VERSION "CAN-LoRa telemetry, protocol version 2"

NS_ :

BS_:

BU_: NODE0_HUB NODE1_FRONT NODE2_REAR NODE3_MOTOR HUB

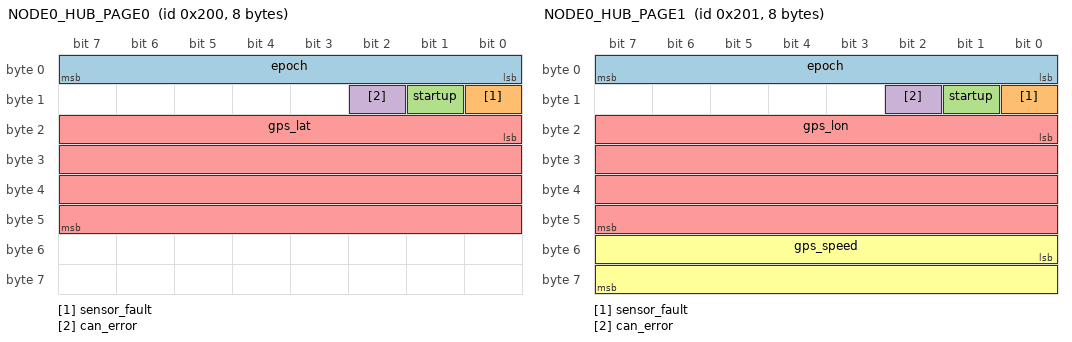
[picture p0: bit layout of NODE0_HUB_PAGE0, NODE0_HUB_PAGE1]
BO_ 512 NODE0_HUB_PAGE0: 8 NODE0_HUB
 SG_ epoch : 0|8@1+ (1,0) [0|255] "" HUB
 SG_ sensor_fault : 8|1@1+ (1,0) [0|1] "" HUB
 SG_ startup : 9|1@1+ (1,0) [0|1] "" HUB
 SG_ can_error : 10|1@1+ (1,0) [0|1] "" HUB
 SG_ gps_lat : 16|32@1- (0.0000001,0) [-214.7483648|214.7483647] "deg" HUB

BO_ 513 NODE0_HUB_PAGE1: 8 NODE0_HUB
 SG_ epoch : 0|8@1+ (1,0) [0|255] "" HUB
 SG_ sensor_fault : 8|1@1+ (1,0) [0|1] "" HUB
 SG_ startup : 9|1@1+ (1,0) [0|1] "" HUB
 SG_ can_error : 10|1@1+ (1,0) [0|1] "" HUB
 SG_ gps_lon : 16|32@1- (0.0000001,0) [-214.7483648|214.7483647] "deg" HUB
 SG_ gps_speed : 48|16@1- (0.01,0) [-327.68|327.67] "mph" HUB

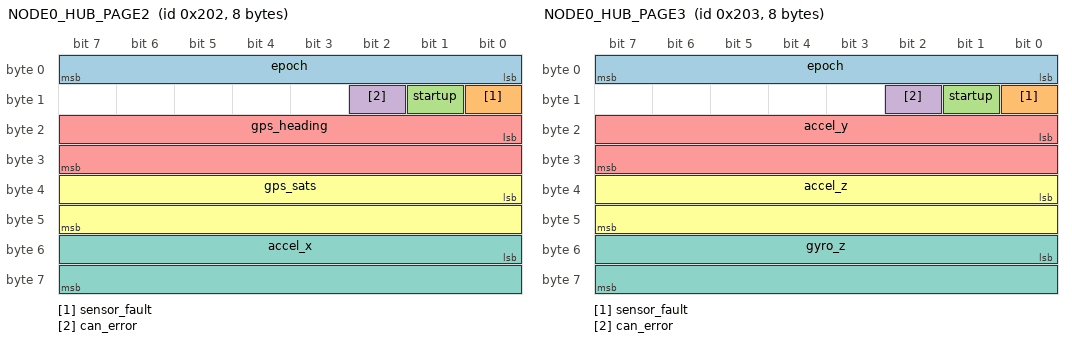
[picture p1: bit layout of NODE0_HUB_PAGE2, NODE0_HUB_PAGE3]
BO_ 514 NODE0_HUB_PAGE2: 8 NODE0_HUB
 SG_ epoch : 0|8@1+ (1,0) [0|255] "" HUB
 SG_ sensor_fault : 8|1@1+ (1,0) [0|1] "" HUB
 SG_ startup : 9|1@1+ (1,0) [0|1] "" HUB
 SG_ can_error : 10|1@1+ (1,0) [0|1] "" HUB
 SG_ gps_heading : 16|16@1- (0.02,0) [-655.36|655.34] "deg" HUB
 SG_ gps_sats : 32|16@1- (1,0) [-32768|32767] "count" HUB
 SG_ accel_x : 48|16@1- (0.001,0) [-32.768|32.767] "g" HUB

BO_ 515 NODE0_HUB_PAGE3: 8 NODE0_HUB
 SG_ epoch : 0|8@1+ (1,0) [0|255] "" HUB
 SG_ sensor_fault : 8|1@1+ (1,0) [0|1] "" HUB
 SG_ startup : 9|1@1+ (1,0) [0|1] "" HUB
 SG_ can_error : 10|1@1+ (1,0) [0|1] "" HUB
 SG_ accel_y : 16|16@1- (0.001,0) [-32.768|32.767] "g" HUB
 SG_ accel_z : 32|16@1- (0.001,0) [-32.768|32.767] "g" HUB
 SG_ gyro_z : 48|16@1- (0.01,0) [-327.68|327.67] "deg/s" HUB

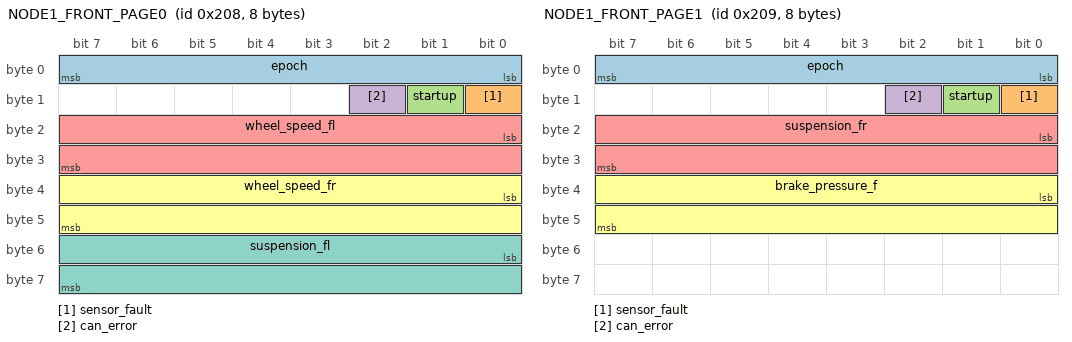
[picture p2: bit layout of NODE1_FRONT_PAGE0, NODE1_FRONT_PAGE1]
BO_ 520 NODE1_FRONT_PAGE0: 8 NODE1_FRONT
 SG_ epoch : 0|8@1+ (1,0) [0|255] "" HUB
 SG_ sensor_fault : 8|1@1+ (1,0) [0|1] "" HUB
 SG_ startup : 9|1@1+ (1,0) [0|1] "" HUB
 SG_ can_error : 10|1@1+ (1,0) [0|1] "" HUB
 SG_ wheel_speed_fl : 16|16@1- (0.01,0) [-327.68|327.67] "mph" HUB
 SG_ wheel_speed_fr : 32|16@1- (0.01,0) [-327.68|327.67] "mph" HUB
 SG_ suspension_fl : 48|16@1- (0.01,0) [-327.68|327.67] "mm" HUB

BO_ 521 NODE1_FRONT_PAGE1: 8 NODE1_FRONT
 SG_ epoch : 0|8@1+ (1,0) [0|255] "" HUB
 SG_ sensor_fault : 8|1@1+ (1,0) [0|1] "" HUB
 SG_ startup : 9|1@1+ (1,0) [0|1] "" HUB
 SG_ can_error : 10|1@1+ (1,0) [0|1] "" HUB
 SG_ suspension_fr : 16|16@1- (0.01,0) [-327.68|327.67] "mm" HUB
 SG_ brake_pressure_f : 32|16@1- (0.1,0) [-3276.8|3276.7000000000003] "psi" HUB

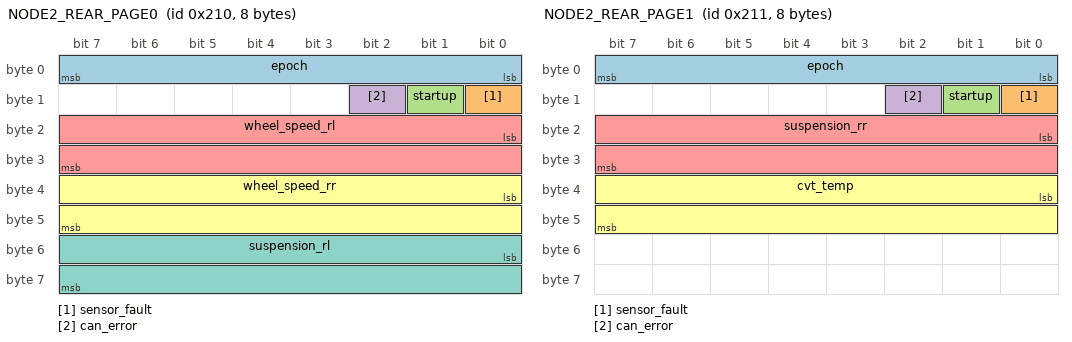
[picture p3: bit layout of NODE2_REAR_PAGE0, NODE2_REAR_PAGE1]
BO_ 528 NODE2_REAR_PAGE0: 8 NODE2_REAR
 SG_ epoch : 0|8@1+ (1,0) [0|255] "" HUB
 SG_ sensor_fault : 8|1@1+ (1,0) [0|1] "" HUB
 SG_ startup : 9|1@1+ (1,0) [0|1] "" HUB
 SG_ can_error : 10|1@1+ (1,0) [0|1] "" HUB
 SG_ wheel_speed_rl : 16|16@1- (0.01,0) [-327.68|327.67] "mph" HUB
 SG_ wheel_speed_rr : 32|16@1- (0.01,0) [-327.68|327.67] "mph" HUB
 SG_ suspension_rl : 48|16@1- (0.01,0) [-327.68|327.67] "mm" HUB

BO_ 529 NODE2_REAR_PAGE1: 8 NODE2_REAR
 SG_ epoch : 0|8@1+ (1,0) [0|255] "" HUB
 SG_ sensor_fault : 8|1@1+ (1,0) [0|1] "" HUB
 SG_ startup : 9|1@1+ (1,0) [0|1] "" HUB
 SG_ can_error : 10|1@1+ (1,0) [0|1] "" HUB
 SG_ suspension_rr : 16|16@1- (0.01,0) [-327.68|327.67] "mm" HUB
 SG_ cvt_temp : 32|16@1- (0.01,0) [-327.68|327.67] "degC" HUB

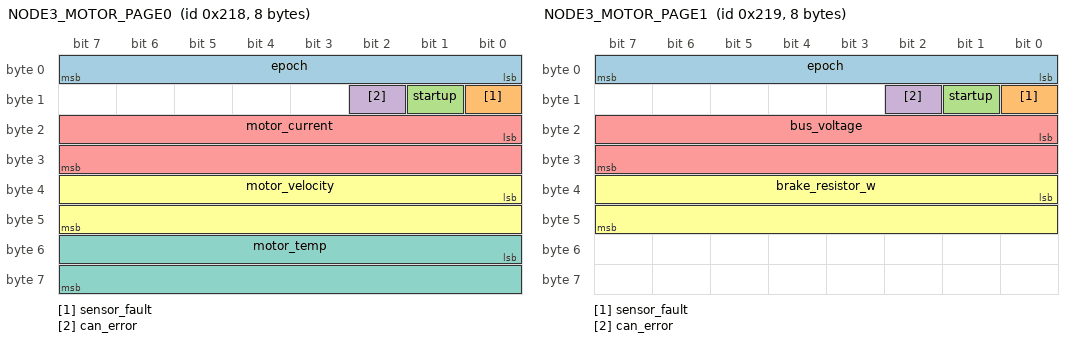
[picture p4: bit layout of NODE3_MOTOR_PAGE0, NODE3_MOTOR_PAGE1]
BO_ 536 NODE3_MOTOR_PAGE0: 8 NODE3_MOTOR
 SG_ epoch : 0|8@1+ (1,0) [0|255] "" HUB
 SG_ sensor_fault : 8|1@1+ (1,0) [0|1] "" HUB
 SG_ startup : 9|1@1+ (1,0) [0|1] "" HUB
 SG_ can_error : 10|1@1+ (1,0) [0|1] "" HUB
 SG_ motor_current : 16|16@1- (0.01,0) [-327.68|327.67] "A" HUB
 SG_ motor_velocity : 32|16@1- (1,0) [-32768|32767] "rpm" HUB
 SG_ motor_temp : 48|16@1- (0.01,0) [-327.68|327.67] "degC" HUB

BO_ 537 NODE3_MOTOR_PAGE1: 8 NODE3_MOTOR
 SG_ epoch : 0|8@1+ (1,0) [0|255] "" HUB
 SG_ sensor_fault : 8|1@1+ (1,0) [0|1] "" HUB
 SG_ startup : 9|1@1+ (1,0) [0|1] "" HUB
 SG_ can_error : 10|1@1+ (1,0) [0|1] "" HUB
 SG_ bus_voltage : 16|16@1- (0.01,0) [-327.68|327.67] "V" HUB
 SG_ brake_resistor_w : 32|16@1- (0.01,0) [-327.68|327.67] "W" HUB

CM_ "Generated by tools/gen_dbc_v2.py on 2026-08-16. Do not edit by hand - edit TLM2_CHANNELS in protocol/telemetry_proto_v2.c and regenerate.";
CM_ BU_ NODE0_HUB "Hub - GPS/IMU, sends 4 page(s) per burst";
CM_ BO_ 512 "Hub - GPS/IMU page 0 of 4, part of a burst sent every 100 ms. All pages of a burst share the same epoch value.";
CM_ SG_ 512 epoch "Increments once per BURST (all pages of one transmit cycle share a value), not once per CAN frame. A gap here means a whole burst was lost or torn, not just this page.";
CM_ SG_ 512 sensor_fault "node could not read a sensor";
CM_ SG_ 512 startup "first few seconds after reset";
CM_ SG_ 512 can_error "node saw bus errors / recovered";
CM_ BO_ 513 "Hub - GPS/IMU page 1 of 4, part of a burst sent every 100 ms. All pages of a burst share the same epoch value.";
CM_ SG_ 513 epoch "Increments once per BURST (all pages of one transmit cycle share a value), not once per CAN frame. A gap here means a whole burst was lost or torn, not just this page.";
CM_ SG_ 513 sensor_fault "node could not read a sensor";
CM_ SG_ 513 startup "first few seconds after reset";
CM_ SG_ 513 can_error "node saw bus errors / recovered";
CM_ BO_ 514 "Hub - GPS/IMU page 2 of 4, part of a burst sent every 100 ms. All pages of a burst share the same epoch value.";
CM_ SG_ 514 epoch "Increments once per BURST (all pages of one transmit cycle share a value), not once per CAN frame. A gap here means a whole burst was lost or torn, not just this page.";
CM_ SG_ 514 sensor_fault "node could not read a sensor";
CM_ SG_ 514 startup "first few seconds after reset";
CM_ SG_ 514 can_error "node saw bus errors / recovered";
CM_ BO_ 515 "Hub - GPS/IMU page 3 of 4, part of a burst sent every 100 ms. All pages of a burst share the same epoch value.";
CM_ SG_ 515 epoch "Increments once per BURST (all pages of one transmit cycle share a value), not once per CAN frame. A gap here means a whole burst was lost or torn, not just this page.";
CM_ SG_ 515 sensor_fault "node could not read a sensor";
CM_ SG_ 515 startup "first few seconds after reset";
CM_ SG_ 515 can_error "node saw bus errors / recovered";
CM_ BU_ NODE1_FRONT "Front, sends 2 page(s) per burst";
CM_ BO_ 520 "Front page 0 of 2, part of a burst sent every 100 ms. All pages of a burst share the same epoch value.";
CM_ SG_ 520 epoch "Increments once per BURST (all pages of one transmit cycle share a value), not once per CAN frame. A gap here means a whole burst was lost or torn, not just this page.";
CM_ SG_ 520 sensor_fault "node could not read a sensor";
CM_ SG_ 520 startup "first few seconds after reset";
CM_ SG_ 520 can_error "node saw bus errors / recovered";
CM_ BO_ 521 "Front page 1 of 2, part of a burst sent every 100 ms. All pages of a burst share the same epoch value.";
CM_ SG_ 521 epoch "Increments once per BURST (all pages of one transmit cycle share a value), not once per CAN frame. A gap here means a whole burst was lost or torn, not just this page.";
CM_ SG_ 521 sensor_fault "node could not read a sensor";
CM_ SG_ 521 startup "first few seconds after reset";
CM_ SG_ 521 can_error "node saw bus errors / recovered";
CM_ BU_ NODE2_REAR "Rear, sends 2 page(s) per burst";
CM_ BO_ 528 "Rear page 0 of 2, part of a burst sent every 100 ms. All pages of a burst share the same epoch value.";
CM_ SG_ 528 epoch "Increments once per BURST (all pages of one transmit cycle share a value), not once per CAN frame. A gap here means a whole burst was lost or torn, not just this page.";
CM_ SG_ 528 sensor_fault "node could not read a sensor";
CM_ SG_ 528 startup "first few seconds after reset";
CM_ SG_ 528 can_error "node saw bus errors / recovered";
CM_ BO_ 529 "Rear page 1 of 2, part of a burst sent every 100 ms. All pages of a burst share the same epoch value.";
CM_ SG_ 529 epoch "Increments once per BURST (all pages of one transmit cycle share a value), not once per CAN frame. A gap here means a whole burst was lost or torn, not just this page.";
CM_ SG_ 529 sensor_fault "node could not read a sensor";
CM_ SG_ 529 startup "first few seconds after reset";
CM_ SG_ 529 can_error "node saw bus errors / recovered";
CM_ BU_ NODE3_MOTOR "E-CVT / Motor, sends 2 page(s) per burst";
CM_ BO_ 536 "E-CVT / Motor page 0 of 2, part of a burst sent every 100 ms. All pages of a burst share the same epoch value.";
CM_ SG_ 536 epoch "Increments once per BURST (all pages of one transmit cycle share a value), not once per CAN frame. A gap here means a whole burst was lost or torn, not just this page.";
CM_ SG_ 536 sensor_fault "node could not read a sensor";
CM_ SG_ 536 startup "first few seconds after reset";
CM_ SG_ 536 can_error "node saw bus errors / recovered";
CM_ BO_ 537 "E-CVT / Motor page 1 of 2, part of a burst sent every 100 ms. All pages of a burst share the same epoch value.";
CM_ SG_ 537 epoch "Increments once per BURST (all pages of one transmit cycle share a value), not once per CAN frame. A gap here means a whole burst was lost or torn, not just this page.";
CM_ SG_ 537 sensor_fault "node could not read a sensor";
CM_ SG_ 537 startup "first few seconds after reset";
CM_ SG_ 537 can_error "node saw bus errors / recovered";
CM_ BU_ HUB "STM32L476RG, aggregates the bus and uplinks snapshots over LoRa";

BA_DEF_ BO_  "GenMsgCycleTime" INT 0 65535;
BA_DEF_ "BusType" STRING ;
BA_DEF_DEF_  "GenMsgCycleTime" 0;
BA_DEF_DEF_  "BusType" "CAN";
BA_ "GenMsgCycleTime" BO_ 512 100;
BA_ "GenMsgCycleTime" BO_ 513 100;
BA_ "GenMsgCycleTime" BO_ 514 100;
BA_ "GenMsgCycleTime" BO_ 515 100;
BA_ "GenMsgCycleTime" BO_ 520 100;
BA_ "GenMsgCycleTime" BO_ 521 100;
BA_ "GenMsgCycleTime" BO_ 528 100;
BA_ "GenMsgCycleTime" BO_ 529 100;
BA_ "GenMsgCycleTime" BO_ 536 100;
BA_ "GenMsgCycleTime" BO_ 537 100;

VAL_ 512 sensor_fault 1 "yes" 0 "no";
VAL_ 512 startup 1 "yes" 0 "no";
VAL_ 512 can_error 1 "yes" 0 "no";
VAL_ 513 sensor_fault 1 "yes" 0 "no";
VAL_ 513 startup 1 "yes" 0 "no";
VAL_ 513 can_error 1 "yes" 0 "no";
VAL_ 514 sensor_fault 1 "yes" 0 "no";
VAL_ 514 startup 1 "yes" 0 "no";
VAL_ 514 can_error 1 "yes" 0 "no";
VAL_ 515 sensor_fault 1 "yes" 0 "no";
VAL_ 515 startup 1 "yes" 0 "no";
VAL_ 515 can_error 1 "yes" 0 "no";
VAL_ 520 sensor_fault 1 "yes" 0 "no";
VAL_ 520 startup 1 "yes" 0 "no";
VAL_ 520 can_error 1 "yes" 0 "no";
VAL_ 521 sensor_fault 1 "yes" 0 "no";
VAL_ 521 startup 1 "yes" 0 "no";
VAL_ 521 can_error 1 "yes" 0 "no";
VAL_ 528 sensor_fault 1 "yes" 0 "no";
VAL_ 528 startup 1 "yes" 0 "no";
VAL_ 528 can_error 1 "yes" 0 "no";
VAL_ 529 sensor_fault 1 "yes" 0 "no";
VAL_ 529 startup 1 "yes" 0 "no";
VAL_ 529 can_error 1 "yes" 0 "no";
VAL_ 536 sensor_fault 1 "yes" 0 "no";
VAL_ 536 startup 1 "yes" 0 "no";
VAL_ 536 can_error 1 "yes" 0 "no";
VAL_ 537 sensor_fault 1 "yes" 0 "no";
VAL_ 537 startup 1 "yes" 0 "no";
VAL_ 537 can_error 1 "yes" 0 "no";
